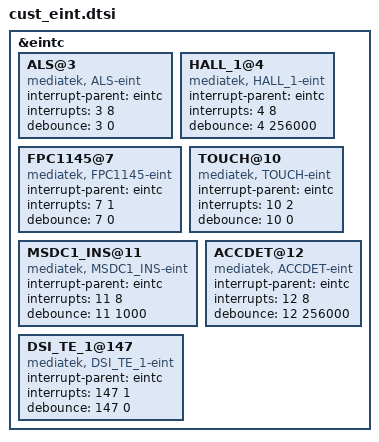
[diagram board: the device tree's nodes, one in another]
/*
 * Generated by MTK SP DrvGen Version 03.13.6 for MT6735M. Copyright MediaTek Inc. (C) 2013.
 * Mon Oct 24 16:08:25 2016
 * Do Not Modify the File.
 */

/*************************
 * EINT DTSI File
*************************/

&eintc {
	ALS@3 {
		compatible = "mediatek, ALS-eint";
		interrupt-parent = <&eintc>;
		interrupts = <3 8>;
		debounce = <3 0>;
	};

	HALL_1@4 {
		compatible = "mediatek, HALL_1-eint";
		interrupt-parent = <&eintc>;
		interrupts = <4 8>;
		debounce = <4 256000>;
	};

	FPC1145@7 {
		compatible = "mediatek, FPC1145-eint";
		interrupt-parent = <&eintc>;
		interrupts = <7 1>;
		debounce = <7 0>;
	};

	TOUCH@10 {
		compatible = "mediatek, TOUCH-eint";
		interrupt-parent = <&eintc>;
		interrupts = <10 2>;
		debounce = <10 0>;
	};

	MSDC1_INS@11 {
		compatible = "mediatek, MSDC1_INS-eint";
		interrupt-parent = <&eintc>;
		interrupts = <11 8>;
		debounce = <11 1000>;
	};

	ACCDET@12 {
		compatible = "mediatek, ACCDET-eint";
		interrupt-parent = <&eintc>;
		interrupts = <12 8>;
		debounce = <12 256000>;
	};

	DSI_TE_1@147 {
		compatible = "mediatek, DSI_TE_1-eint";
		interrupt-parent = <&eintc>;
		interrupts = <147 1>;
		debounce = <147 0>;
	};

};
